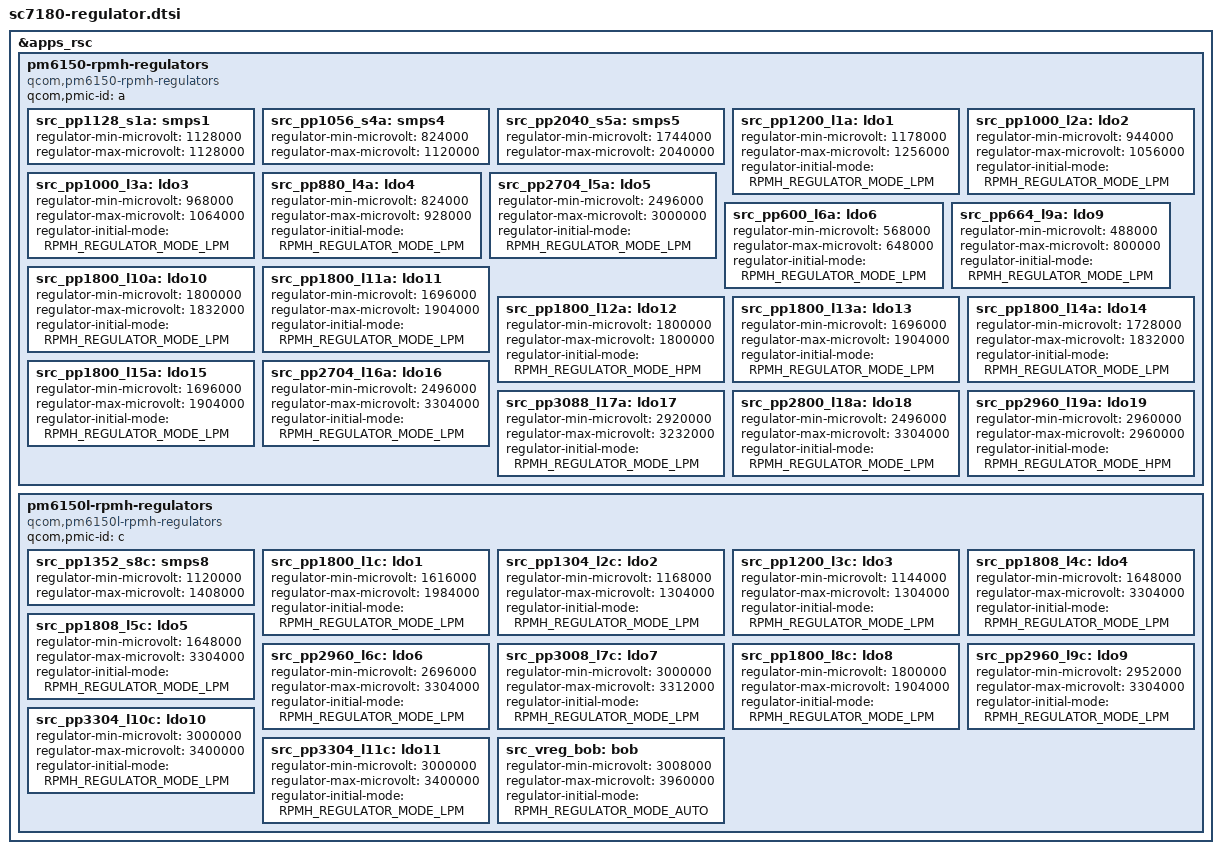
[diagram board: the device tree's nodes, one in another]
// SPDX-License-Identifier: GPL-2.0
// Copyright (c) 2019, The Linux Foundation. All rights reserved.

#include <dt-bindings/regulator/qcom,rpmh-regulator.h>

&apps_rsc {
	pm6150-rpmh-regulators {
		compatible = "qcom,pm6150-rpmh-regulators";
		qcom,pmic-id = "a";

		src_pp1128_s1a: smps1 {
			regulator-min-microvolt = <1128000>;
			regulator-max-microvolt = <1128000>;
		};

		src_pp1056_s4a: smps4 {
			regulator-min-microvolt = <824000>;
			regulator-max-microvolt = <1120000>;
		};

		src_pp2040_s5a: smps5 {
			regulator-min-microvolt = <1744000>;
			regulator-max-microvolt = <2040000>;
		};

		src_pp1200_l1a: ldo1 {
			regulator-min-microvolt = <1178000>;
			regulator-max-microvolt = <1256000>;
			regulator-initial-mode = <RPMH_REGULATOR_MODE_LPM>;
		};

		src_pp1000_l2a: ldo2 {
			regulator-min-microvolt = <944000>;
			regulator-max-microvolt = <1056000>;
			regulator-initial-mode = <RPMH_REGULATOR_MODE_LPM>;
		};

		src_pp1000_l3a: ldo3 {
			regulator-min-microvolt = <968000>;
			regulator-max-microvolt = <1064000>;
			regulator-initial-mode = <RPMH_REGULATOR_MODE_LPM>;
		};

		src_pp880_l4a: ldo4 {
			regulator-min-microvolt = <824000>;
			regulator-max-microvolt = <928000>;
			regulator-initial-mode = <RPMH_REGULATOR_MODE_LPM>;
		};

		src_pp2704_l5a: ldo5 {
			regulator-min-microvolt = <2496000>;
			regulator-max-microvolt = <3000000>;
			regulator-initial-mode = <RPMH_REGULATOR_MODE_LPM>;
		};

		src_pp600_l6a: ldo6 {
			regulator-min-microvolt = <568000>;
			regulator-max-microvolt = <648000>;
			regulator-initial-mode = <RPMH_REGULATOR_MODE_LPM>;
		};

		src_pp664_l9a: ldo9 {
			regulator-min-microvolt = <488000>;
			regulator-max-microvolt = <800000>;
			regulator-initial-mode = <RPMH_REGULATOR_MODE_LPM>;
		};

		src_pp1800_l10a: ldo10 {
			regulator-min-microvolt = <1800000>;
			regulator-max-microvolt = <1832000>;
			regulator-initial-mode = <RPMH_REGULATOR_MODE_LPM>;
		};

		src_pp1800_l11a: ldo11 {
			regulator-min-microvolt = <1696000>;
			regulator-max-microvolt = <1904000>;
			regulator-initial-mode = <RPMH_REGULATOR_MODE_LPM>;
		};

		src_pp1800_l12a: ldo12 {
			regulator-min-microvolt = <1800000>;
			regulator-max-microvolt = <1800000>;
			regulator-initial-mode = <RPMH_REGULATOR_MODE_HPM>;
		};

		src_pp1800_l13a: ldo13 {
			regulator-min-microvolt = <1696000>;
			regulator-max-microvolt = <1904000>;
			regulator-initial-mode = <RPMH_REGULATOR_MODE_LPM>;
		};

		src_pp1800_l14a: ldo14 {
			regulator-min-microvolt = <1728000>;
			regulator-max-microvolt = <1832000>;
			regulator-initial-mode = <RPMH_REGULATOR_MODE_LPM>;
		};

		src_pp1800_l15a: ldo15 {
			regulator-min-microvolt = <1696000>;
			regulator-max-microvolt = <1904000>;
			regulator-initial-mode = <RPMH_REGULATOR_MODE_LPM>;
		};

		src_pp2704_l16a: ldo16 {
			regulator-min-microvolt = <2496000>;
			regulator-max-microvolt = <3304000>;
			regulator-initial-mode = <RPMH_REGULATOR_MODE_LPM>;
		};

		src_pp3088_l17a: ldo17 {
			regulator-min-microvolt = <2920000>;
			regulator-max-microvolt = <3232000>;
			regulator-initial-mode = <RPMH_REGULATOR_MODE_LPM>;
		};

		src_pp2800_l18a: ldo18 {
			regulator-min-microvolt = <2496000>;
			regulator-max-microvolt = <3304000>;
			regulator-initial-mode = <RPMH_REGULATOR_MODE_LPM>;
		};

		src_pp2960_l19a: ldo19 {
			regulator-min-microvolt = <2960000>;
			regulator-max-microvolt = <2960000>;
			regulator-initial-mode = <RPMH_REGULATOR_MODE_HPM>;
		};
	};

	pm6150l-rpmh-regulators {
		compatible = "qcom,pm6150l-rpmh-regulators";
		qcom,pmic-id = "c";

		src_pp1352_s8c: smps8 {
			regulator-min-microvolt = <1120000>;
			regulator-max-microvolt = <1408000>;
		};

		src_pp1800_l1c: ldo1 {
			regulator-min-microvolt = <1616000>;
			regulator-max-microvolt = <1984000>;
			regulator-initial-mode = <RPMH_REGULATOR_MODE_LPM>;
		};

		src_pp1304_l2c: ldo2 {
			regulator-min-microvolt = <1168000>;
			regulator-max-microvolt = <1304000>;
			regulator-initial-mode = <RPMH_REGULATOR_MODE_LPM>;
		};

		src_pp1200_l3c: ldo3 {
			regulator-min-microvolt = <1144000>;
			regulator-max-microvolt = <1304000>;
			regulator-initial-mode = <RPMH_REGULATOR_MODE_LPM>;
		};

		src_pp1808_l4c: ldo4 {
			regulator-min-microvolt = <1648000>;
			regulator-max-microvolt = <3304000>;
			regulator-initial-mode = <RPMH_REGULATOR_MODE_LPM>;
		};

		src_pp1808_l5c: ldo5 {
			regulator-min-microvolt = <1648000>;
			regulator-max-microvolt = <3304000>;
			regulator-initial-mode = <RPMH_REGULATOR_MODE_LPM>;
		};

		src_pp2960_l6c: ldo6 {
			regulator-min-microvolt = <2696000>;
			regulator-max-microvolt = <3304000>;
			regulator-initial-mode = <RPMH_REGULATOR_MODE_LPM>;
		};

		src_pp3008_l7c: ldo7 {
			regulator-min-microvolt = <3000000>;
			regulator-max-microvolt = <3312000>;
			regulator-initial-mode = <RPMH_REGULATOR_MODE_LPM>;
		};

		src_pp1800_l8c: ldo8 {
			regulator-min-microvolt = <1800000>;
			regulator-max-microvolt = <1904000>;
			regulator-initial-mode = <RPMH_REGULATOR_MODE_LPM>;
		};

		src_pp2960_l9c: ldo9 {
			regulator-min-microvolt = <2952000>;
			regulator-max-microvolt = <3304000>;
			regulator-initial-mode = <RPMH_REGULATOR_MODE_LPM>;
		};

		src_pp3304_l10c: ldo10 {
			regulator-min-microvolt = <3000000>;
			regulator-max-microvolt = <3400000>;
			regulator-initial-mode = <RPMH_REGULATOR_MODE_LPM>;
		};

		src_pp3304_l11c: ldo11 {
			regulator-min-microvolt = <3000000>;
			regulator-max-microvolt = <3400000>;
			regulator-initial-mode = <RPMH_REGULATOR_MODE_LPM>;
		};

		src_vreg_bob: bob {
			regulator-min-microvolt = <3008000>;
			regulator-max-microvolt = <3960000>;
			regulator-initial-mode = <RPMH_REGULATOR_MODE_AUTO>;
		};
	};
};
